# V32F20x_CM33 register map
File version: 1.0.3
CPU: CM33 r0p4, little endian, MPU, FPU, DSP, 3 interrupt priority bits, 8 SAU regions
Registers are 32-bit, read-write, reset 0x0 unless marked. A register's access mark holds for its fields unless they carry their own. Offsets are from the block's base; [hi:lo] are bit positions; {n}, {i} and the like mark numbered series.

## IOCTRL — IOCTRL Peripheral Interface
Base 0x40106400
Same registers: SEC_IOCTRL 0x50106400
0x00 IOA_IS — IOA IS signal configure register.
  [15:0] IOA_IS — Input mode controlling signal IOA0~15 IS configure
0x04 IOB_IS — IOB IS signal configure register.
  [15:0] IOB_IS — Input mode controlling signal IOB0~15 IS configure
0x08 IOC_IS — IOC IS signal configure register.
  [15:0] IOC_IS — Input mode controlling signal IOC0~15 IS configure
0x0C IOD_IS — IOD IS signal configure register.
  [15:0] IOD_IS — Input mode controlling signal IOD0~15 IS configure
0x10 IOE_IS — IOE IS signal configure register.
  [15:0] IOE_IS — Input mode controlling signal IOE0~15 IS configure
0x14 IOF_IS — IOF IS signal configure register.
  [15:0] IOF_IS — Input mode controlling signal IOF0~15 IS configure
0x18 IOG_IS — IOG IS signal configure register.
  [15:0] IOG_IS — Input mode controlling signal IOG0~15 IS configure
0x1C IOH_IS — IOH IS signal configure register.
  [15:0] IOH_IS — Input mode controlling signal IOH0~15 IS configure
0x20 IOI_IS — IOI IS signal configure register.
  [15:0] IOI_IS — Input mode controlling signal IOI0~15 IS configure
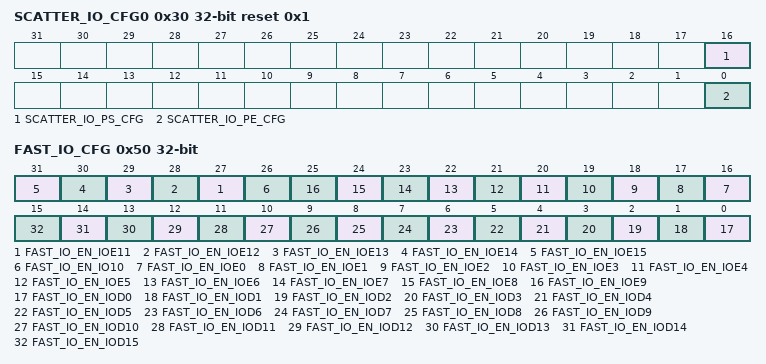
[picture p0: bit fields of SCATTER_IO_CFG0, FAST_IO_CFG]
0x30 SCATTER_IO_CFG0 reset 0x1 — SCATTER IO PE/PS signal configure register.
  [16] SCATTER_IO_PS_CFG — External reset IO PS configure
  [0] SCATTER_IO_PE_CFG — External reset IO PE configure
0x34 SCATTER_IO_CFG1 — SCATTER_IO_CFG1 IS signal configure register.
  [0] SCATTER_IO_IS — External reset IS configure
0x38 SCATTER_IO_CFG2 wo reset 0x2 — SCATTER_IO DR configure register.
  [1:0] SCATTER_IO_DR — External reset DR configure:
0x50 FAST_IO_CFG — Fast IO enable control.
  [n+16] FAST_IO_EN_IOE{n} (n=11..15) — Fast IO mode enable for IOE{n}
  [26] FAST_IO_EN_IO10 — Fast IO mode enable for IOE10
  [n+16] FAST_IO_EN_IOE{n} (n=0..9) — Fast IO mode enable for IOE{n}
  [n] FAST_IO_EN_IOD{n} (n=0..15) — Fast IO mode enable for IOD{n}

## EXTI — EXTI Peripheral Interface
Base 0x40106800
Same registers: SEC_EXTI 0x50106800
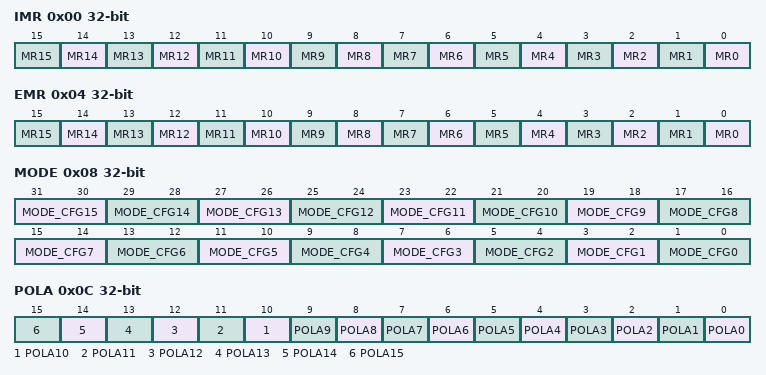
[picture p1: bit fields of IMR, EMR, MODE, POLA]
0x00 IMR — EXTI interrupt mask register
  [n] MR{n} (n=0..15) — Interrupt mask on line{n}
0x04 EMR — EXTI wakeup mask register
  [n] MR{n} (n=0..15) — Wakeup mask on line{n}
0x08 MODE — EXTI interrupt and wakerup mode configure register
  [31:30] MODE_CFG15 — The mode of line15 interrupt and wakeup configure:
  [29:28] MODE_CFG14 — The mode of line14 interrupt and wakeup configure:
  [27:26] MODE_CFG13 — The mode of line13 nterrupt and wakeup configure:
  [2n+1:2n] MODE_CFG{n} (n=4..12) — The mode of line{n} interrupt and wakeup configure:
  [7:6] MODE_CFG3 — The mode of linre3 interrupt and wakeup configure:
  [5:4] MODE_CFG2 — The mode of line2 interrupt and wakeup configure:
  [3:2] MODE_CFG1 — The mode of line1 interrupt and wakeup configure:
  [1:0] MODE_CFG0 — The mode of line0 interrupt and wakeup configure:
0x0C POLA — EXTI interrupt and wakerup polarity configure register
  [n] POLA{n} (n=0..15) — The polarity of line{n} interrupt and wakeup configure
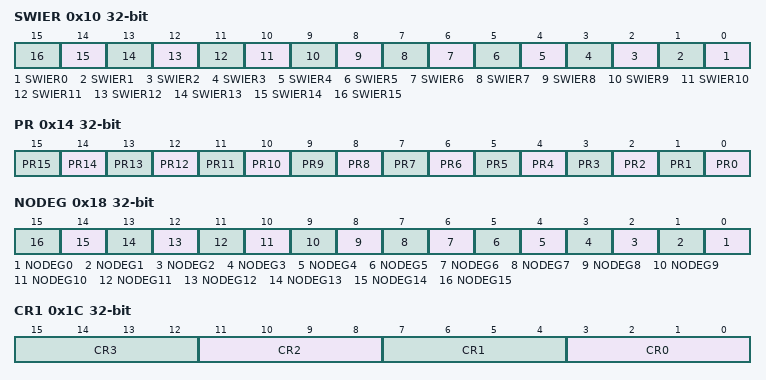
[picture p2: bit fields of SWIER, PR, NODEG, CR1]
0x10 SWIER — Interrupt software control register
  [n] SWIER{n} (n=0..15) — Software Interrupt on line{n}
0x14 PR — EXTI interrupt pending register
  [n] PR{n} (n=0..15) — Pending bit of line{n}
0x18 NODEG — External input signal deglitch control register
  [n] NODEG{n} (n=0..15) — Line{n} external input signal deglitch disable:
0x1C CR1 — EXTI input pin select register1
  [4n+3:4n] CR{n} (n=0..3) — EXTI line{n} input pin selection:
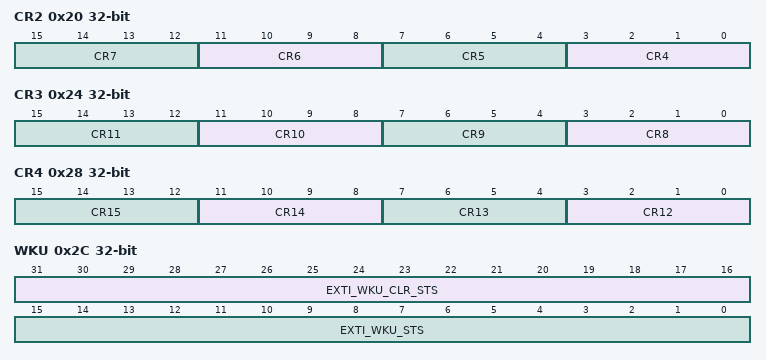
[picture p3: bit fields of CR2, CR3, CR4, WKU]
0x20 CR2 — EXTI input pin select register2
  [4n-13:4n-16] CR{n} (n=4..7) — EXTI line{n} input pin selection:
0x24 CR3 — EXTI input pin select register3
  [4n-29:4n-32] CR{n} (n=8..11) — EXTI line{n} input pin selection:
0x28 CR4 — EXTI input pin select register4
  [4n-45:4n-48] CR{n} (n=12..15) — EXTI line{n} input pin selection:
0x2C WKU — EXTI wakeup status and clear register
  [31:16] EXTI_WKU_CLR_STS — EXTI_WKU_STS clear status
  [15:0] EXTI_WKU_STS — 1: Corresponding EXTI wake up occured
